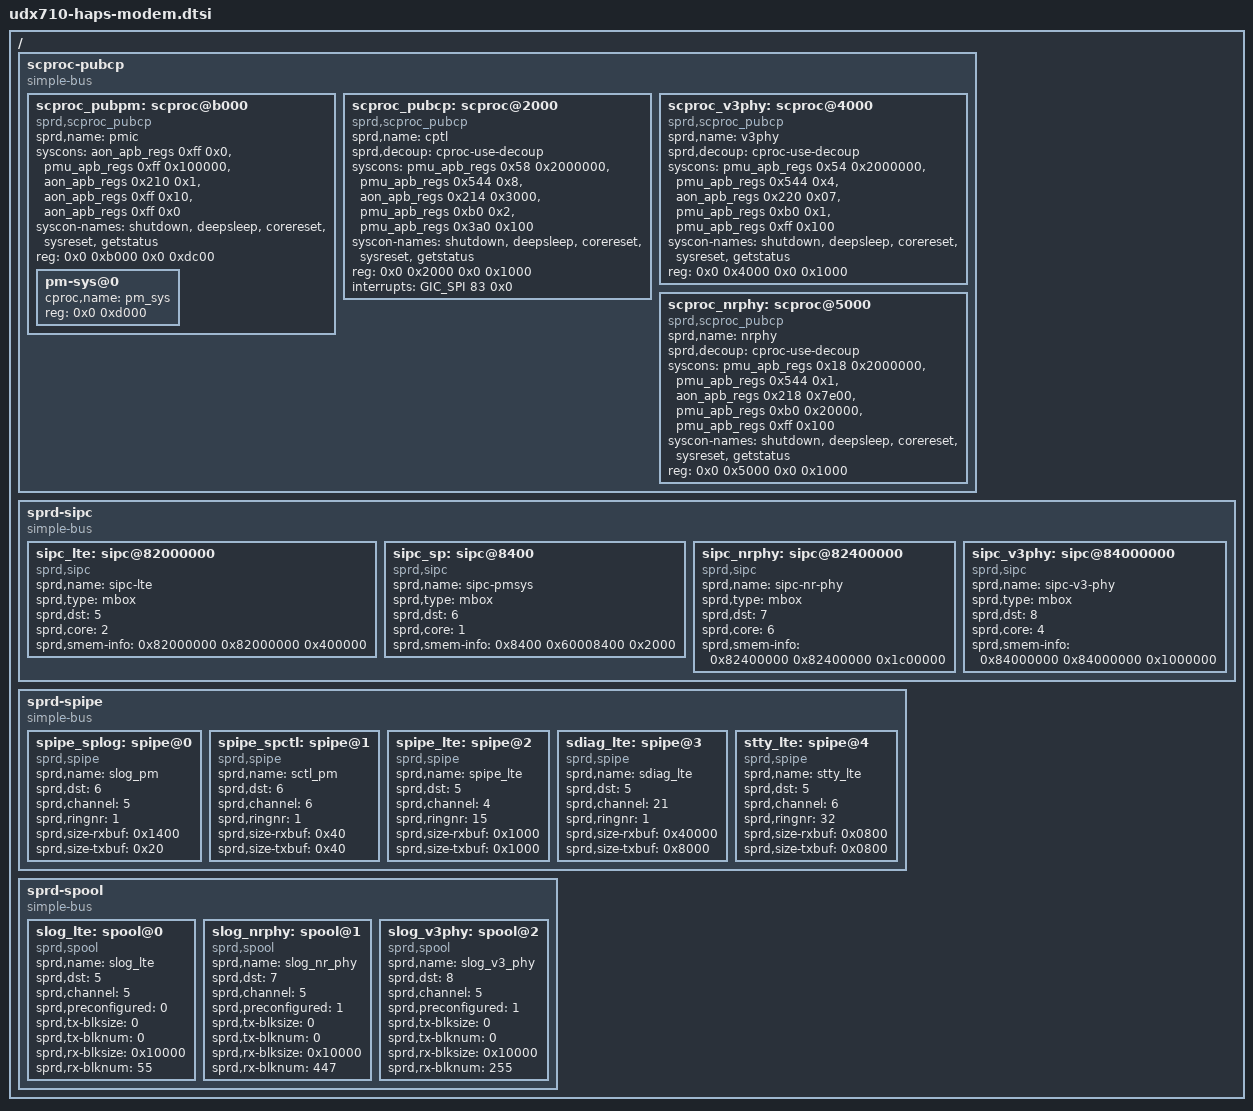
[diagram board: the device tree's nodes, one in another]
/*
 * Spreadtrum UDX710 HAPS MODEM board DTSI file
 * This dt is used for modem drivers
 *
 * Copyright (C) 2018, Spreadtrum Communications Inc.
 *
 * This file is licensed under a dual GPLv2 or X11 license.
 */

/ {
	scproc-pubcp {
		compatible = "simple-bus";
		#address-cells = <2>;
		#size-cells = <2>;
		ranges;

		scproc_pubpm: scproc@b000 {
			compatible = "sprd,scproc_pubcp";
			sprd,name = "pmic";
			syscons = <&aon_apb_regs 0xff 0x0>,
				  <&pmu_apb_regs 0xff 0x100000>,
				  <&aon_apb_regs 0x210 0x1>,
				  <&aon_apb_regs 0xff 0x10>,
				  <&aon_apb_regs 0xff 0x0>;
			syscon-names = "shutdown", "deepsleep", "corereset",
				       "sysreset", "getstatus";
			reg = <0x0 0xb000 0x0 0xdc00>;
			#address-cells = <1>;
			#size-cells = <1>;
			/* segnr=1 */
			ranges = <0x0 0x0 0xa400 0xd000>;
			pm-sys@0 {
				cproc,name = "pm_sys";
				reg = <0x0 0xd000>;
			};
		};

		scproc_pubcp: scproc@2000 {
			sprd,name = "cptl";
			compatible = "sprd,scproc_pubcp";
			sprd,decoup = "cproc-use-decoup";
			syscons = <&pmu_apb_regs 0x58 0x2000000>,
				  <&pmu_apb_regs 0x544 0x8>,
				  <&aon_apb_regs 0x214 0x3000>,
				  <&pmu_apb_regs 0xb0 0x2>,
				  <&pmu_apb_regs 0x3a0 0x100>;
			syscon-names = "shutdown", "deepsleep", "corereset",
				       "sysreset", "getstatus";
			reg = <0x0 0x2000 0x0 0x1000>;
			/* Interrupt to be confirmed.*/
			interrupts = <GIC_SPI 83 0x0>;
		};

		scproc_v3phy: scproc@4000 {
			sprd,name = "v3phy";
			compatible = "sprd,scproc_pubcp";
			sprd,decoup = "cproc-use-decoup";
			syscons = <&pmu_apb_regs 0x54 0x2000000>,
			<&pmu_apb_regs 0x544 0x4>,
			<&aon_apb_regs 0x220 0x07>,
			<&pmu_apb_regs 0xb0 0x1>,
			<&pmu_apb_regs 0xff 0x100>;
			syscon-names = "shutdown", "deepsleep", "corereset",
				       "sysreset", "getstatus";
			reg = <0x0 0x4000 0x0 0x1000>;
		};

		scproc_nrphy: scproc@5000 {
			sprd,name = "nrphy";
			compatible = "sprd,scproc_pubcp";
			sprd,decoup = "cproc-use-decoup";
			syscons = <&pmu_apb_regs 0x18 0x2000000>,
			<&pmu_apb_regs 0x544 0x1>,
			<&aon_apb_regs 0x218 0x7e00>,
			<&pmu_apb_regs 0xb0 0x20000>,
			<&pmu_apb_regs 0xff 0x100>;
			syscon-names = "shutdown", "deepsleep", "corereset",
				       "sysreset", "getstatus";
			reg = <0x0 0x5000 0x0 0x1000>;
		};
	};

	sprd-sipc {
		compatible = "simple-bus";
		#address-cells = <1>;
		#size-cells = <1>;
		ranges;

		/* PSP: 4MB */
		sipc_lte: sipc@82000000 {
			compatible = "sprd,sipc";
			sprd,name = "sipc-lte";
			sprd,type = "mbox";
			sprd,dst = <5>;
			sprd,core = <2>;
			sprd,smem-info = <0x82000000 0x82000000 0x400000>;
		};

		/* PM subsystem: 8KB */
		sipc_sp: sipc@8400 {
			compatible = "sprd,sipc";
			sprd,name = "sipc-pmsys";
			sprd,type = "mbox";
			sprd,dst = <6>;
			sprd,core = <1>;
			sprd,smem-info = <0x8400 0x60008400 0x2000>;
		};

		/* New Radio PHY: 28MB */
		sipc_nrphy: sipc@82400000 {
			compatible = "sprd,sipc";
			sprd,name = "sipc-nr-phy";
			sprd,type = "mbox";
			sprd,dst = <7>;
			sprd,core = <6>;
			sprd,smem-info = <0x82400000 0x82400000 0x1c00000>;
		};

		/* MODEM v3 PHY: 16MB */
		sipc_v3phy: sipc@84000000 {
			compatible = "sprd,sipc";
			sprd,name = "sipc-v3-phy";
			sprd,type = "mbox";
			sprd,dst = <8>;
			sprd,core = <4>;
			sprd,smem-info = <0x84000000 0x84000000 0x1000000>;
		};
	};

	sprd-spipe {
		compatible = "simple-bus";
		#address-cells = <1>;
		#size-cells = <1>;
		ranges;

		spipe_splog: spipe@0 {
			compatible = "sprd,spipe";
			sprd,name = "slog_pm";
			sprd,dst = <6>;
			sprd,channel = <5>;
			sprd,ringnr = <1>;
			sprd,size-rxbuf = <0x1400>;	/* 5KB */
			sprd,size-txbuf = <0x20>;	/* 32 */
		};

		spipe_spctl: spipe@1 {
			compatible = "sprd,spipe";
			sprd,name = "sctl_pm";
			sprd,dst = <6>;
			sprd,channel = <6>;
			sprd,ringnr = <1>;
			sprd,size-rxbuf = <0x40>;
			sprd,size-txbuf = <0x40>;
		};

		/* PSP spipe: 8KB x 15 = 120KB */
		spipe_lte: spipe@2 {
			compatible = "sprd,spipe";
			sprd,name = "spipe_lte";
			sprd,dst = <5>;
			sprd,channel = <4>;
			sprd,ringnr = <15>;
			sprd,size-rxbuf = <0x1000>; /* 4*1024 */
			sprd,size-txbuf = <0x1000>; /* 4*1024 */
		};

		/* PSP diag: 288KB */
		sdiag_lte: spipe@3 {
			compatible = "sprd,spipe";
			sprd,name = "sdiag_lte";
			sprd,dst = <5>;
			sprd,channel = <21>;
			sprd,ringnr = <1>;
			sprd,size-rxbuf = <0x40000>; /* 256*1024*/
			sprd,size-txbuf = <0x8000>; /* 32*1024 */
		};

		/* PSP tty: 4KB x 32 = 128KB */
		stty_lte: spipe@4 {
			compatible = "sprd,spipe";
			sprd,name = "stty_lte";
			sprd,dst = <5>;
			sprd,channel = <6>;
			sprd,ringnr = <32>;
			sprd,size-rxbuf = <0x0800>; /* 2*1024*/
			sprd,size-txbuf = <0x0800>; /* 2*1024 */
		};
	};

	sprd-spool {
		compatible = "simple-bus";
		#address-cells = <1>;
		#size-cells = <1>;
		ranges;

		/* PSP log: 64KB x 55 = 3520KB */
		slog_lte: spool@0 {
			compatible = "sprd,spool";
			sprd,name = "slog_lte";
			sprd,dst = <5>;
			sprd,channel = <5>;
			sprd,preconfigured = <0>;
			sprd,tx-blksize = <0>;
			sprd,tx-blknum = <0>;
			sprd,rx-blksize = <0x10000>;
			sprd,rx-blknum = <55>;
		};

		/* New Radio PHY log: 64KB x 447 = 28608KB */
		slog_nrphy: spool@1 {
			compatible = "sprd,spool";
			sprd,name = "slog_nr_phy";
			sprd,dst = <7>;
			sprd,channel = <5>;
			sprd,preconfigured = <1>;
			sprd,tx-blksize = <0>;
			sprd,tx-blknum = <0>;
			sprd,rx-blksize = <0x10000>;
			sprd,rx-blknum = <447>;
		};

		/* MODEM v3 PHY log: 64KB x 255 = 16320KB */
		slog_v3phy: spool@2 {
			compatible = "sprd,spool";
			sprd,name = "slog_v3_phy";
			sprd,dst = <8>;
			sprd,channel = <5>;
			sprd,preconfigured = <1>;
			sprd,tx-blksize = <0>;
			sprd,tx-blknum = <0>;
			sprd,rx-blksize = <0x10000>;
			sprd,rx-blknum = <255>;
		};
	};
};
